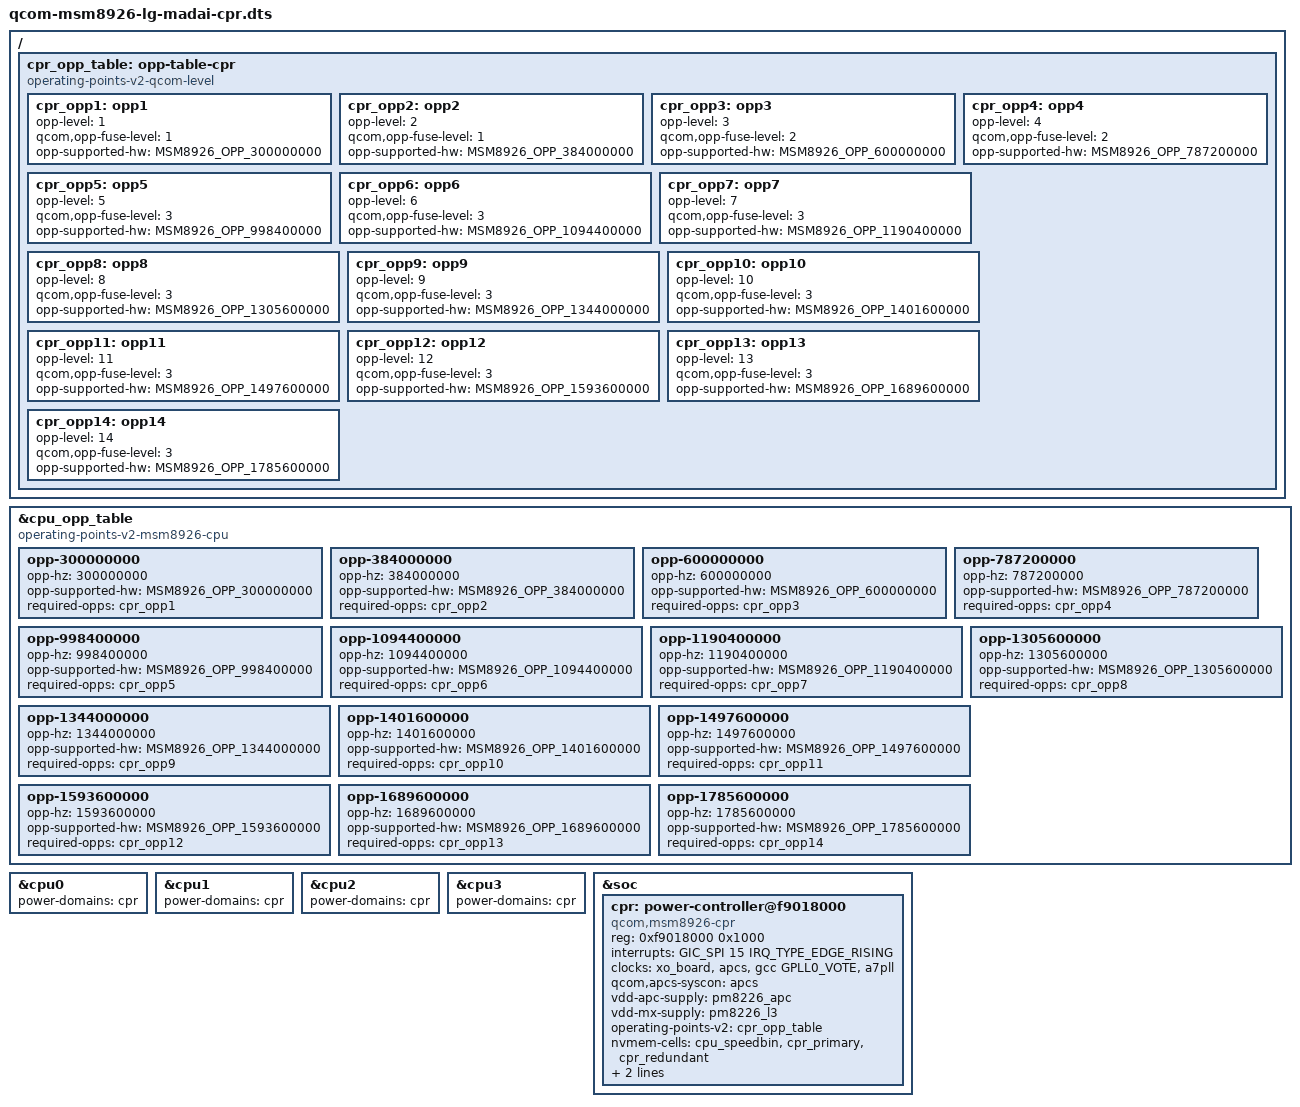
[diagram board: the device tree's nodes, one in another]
// SPDX-License-Identifier: BSD-3-Clause
/*
 * Experimental CPU/CPR qualification target, separate from the ordinary DTB.
 * This validation tree is not a complete reproduction of installed r50.
 * Reconstruct the current integration before RAM-only controller qualification.
 */
#include "qcom-msm8926-lg-madai.dts"
#include <dt-bindings/opp/qcom,msm8926.h>

/ {
	cpr_opp_table: opp-table-cpr {
		compatible = "operating-points-v2-qcom-level";

		cpr_opp1: opp1 {
			opp-level = <1>;
			qcom,opp-fuse-level = <1>;
			opp-supported-hw = <MSM8926_OPP_300000000>;
		};

		cpr_opp2: opp2 {
			opp-level = <2>;
			qcom,opp-fuse-level = <1>;
			opp-supported-hw = <MSM8926_OPP_384000000>;
		};

		cpr_opp3: opp3 {
			opp-level = <3>;
			qcom,opp-fuse-level = <2>;
			opp-supported-hw = <MSM8926_OPP_600000000>;
		};

		cpr_opp4: opp4 {
			opp-level = <4>;
			qcom,opp-fuse-level = <2>;
			opp-supported-hw = <MSM8926_OPP_787200000>;
		};

		cpr_opp5: opp5 {
			opp-level = <5>;
			qcom,opp-fuse-level = <3>;
			opp-supported-hw = <MSM8926_OPP_998400000>;
		};

		cpr_opp6: opp6 {
			opp-level = <6>;
			qcom,opp-fuse-level = <3>;
			opp-supported-hw = <MSM8926_OPP_1094400000>;
		};

		cpr_opp7: opp7 {
			opp-level = <7>;
			qcom,opp-fuse-level = <3>;
			opp-supported-hw = <MSM8926_OPP_1190400000>;
		};

		cpr_opp8: opp8 {
			opp-level = <8>;
			qcom,opp-fuse-level = <3>;
			opp-supported-hw = <MSM8926_OPP_1305600000>;
		};

		cpr_opp9: opp9 {
			opp-level = <9>;
			qcom,opp-fuse-level = <3>;
			opp-supported-hw = <MSM8926_OPP_1344000000>;
		};

		cpr_opp10: opp10 {
			opp-level = <10>;
			qcom,opp-fuse-level = <3>;
			opp-supported-hw = <MSM8926_OPP_1401600000>;
		};

		cpr_opp11: opp11 {
			opp-level = <11>;
			qcom,opp-fuse-level = <3>;
			opp-supported-hw = <MSM8926_OPP_1497600000>;
		};

		cpr_opp12: opp12 {
			opp-level = <12>;
			qcom,opp-fuse-level = <3>;
			opp-supported-hw = <MSM8926_OPP_1593600000>;
		};

		cpr_opp13: opp13 {
			opp-level = <13>;
			qcom,opp-fuse-level = <3>;
			opp-supported-hw = <MSM8926_OPP_1689600000>;
		};

		cpr_opp14: opp14 {
			opp-level = <14>;
			qcom,opp-fuse-level = <3>;
			opp-supported-hw = <MSM8926_OPP_1785600000>;
		};
	};
};

&cpu_opp_table {
	compatible = "operating-points-v2-msm8926-cpu";

	opp-300000000 {
		opp-hz = /bits/ 64 <300000000>;
		opp-supported-hw = <MSM8926_OPP_300000000>;
		required-opps = <&cpr_opp1>;
	};

	opp-384000000 {
		opp-hz = /bits/ 64 <384000000>;
		opp-supported-hw = <MSM8926_OPP_384000000>;
		required-opps = <&cpr_opp2>;
	};

	opp-600000000 {
		opp-hz = /bits/ 64 <600000000>;
		opp-supported-hw = <MSM8926_OPP_600000000>;
		required-opps = <&cpr_opp3>;
	};

	opp-787200000 {
		opp-hz = /bits/ 64 <787200000>;
		opp-supported-hw = <MSM8926_OPP_787200000>;
		required-opps = <&cpr_opp4>;
	};

	opp-998400000 {
		opp-hz = /bits/ 64 <998400000>;
		opp-supported-hw = <MSM8926_OPP_998400000>;
		required-opps = <&cpr_opp5>;
	};

	opp-1094400000 {
		opp-hz = /bits/ 64 <1094400000>;
		opp-supported-hw = <MSM8926_OPP_1094400000>;
		required-opps = <&cpr_opp6>;
	};

	opp-1190400000 {
		opp-hz = /bits/ 64 <1190400000>;
		opp-supported-hw = <MSM8926_OPP_1190400000>;
		required-opps = <&cpr_opp7>;
	};

	opp-1305600000 {
		opp-hz = /bits/ 64 <1305600000>;
		opp-supported-hw = <MSM8926_OPP_1305600000>;
		required-opps = <&cpr_opp8>;
	};

	opp-1344000000 {
		opp-hz = /bits/ 64 <1344000000>;
		opp-supported-hw = <MSM8926_OPP_1344000000>;
		required-opps = <&cpr_opp9>;
	};

	opp-1401600000 {
		opp-hz = /bits/ 64 <1401600000>;
		opp-supported-hw = <MSM8926_OPP_1401600000>;
		required-opps = <&cpr_opp10>;
	};

	opp-1497600000 {
		opp-hz = /bits/ 64 <1497600000>;
		opp-supported-hw = <MSM8926_OPP_1497600000>;
		required-opps = <&cpr_opp11>;
	};

	opp-1593600000 {
		opp-hz = /bits/ 64 <1593600000>;
		opp-supported-hw = <MSM8926_OPP_1593600000>;
		required-opps = <&cpr_opp12>;
	};

	opp-1689600000 {
		opp-hz = /bits/ 64 <1689600000>;
		opp-supported-hw = <MSM8926_OPP_1689600000>;
		required-opps = <&cpr_opp13>;
	};

	opp-1785600000 {
		opp-hz = /bits/ 64 <1785600000>;
		opp-supported-hw = <MSM8926_OPP_1785600000>;
		required-opps = <&cpr_opp14>;
	};
};

&cpu0 {
	power-domains = <&cpr>;
	power-domain-names = "cpr";
};

&cpu1 {
	power-domains = <&cpr>;
	power-domain-names = "cpr";
};

&cpu2 {
	power-domains = <&cpr>;
	power-domain-names = "cpr";
};

&cpu3 {
	power-domains = <&cpr>;
	power-domain-names = "cpr";
};

&soc {
	cpr: power-controller@f9018000 {
		compatible = "qcom,msm8926-cpr", "qcom,cpr";
		reg = <0xf9018000 0x1000>;
		interrupts = <GIC_SPI 15 IRQ_TYPE_EDGE_RISING>;
		clocks = <&xo_board>, <&apcs>, <&gcc GPLL0_VOTE>, <&a7pll>;
		clock-names = "ref", "cpu", "aux", "pll";
		qcom,apcs-syscon = <&apcs>;
		vdd-apc-supply = <&pm8226_apc>;
		vdd-mx-supply = <&pm8226_l3>;
		#power-domain-cells = <0>;
		operating-points-v2 = <&cpr_opp_table>;
		nvmem-cells = <&cpu_speedbin>, <&cpr_primary>, <&cpr_redundant>;
		nvmem-cell-names = "cpu_calibration", "cpr_primary", "cpr_redundant";
	};
};
